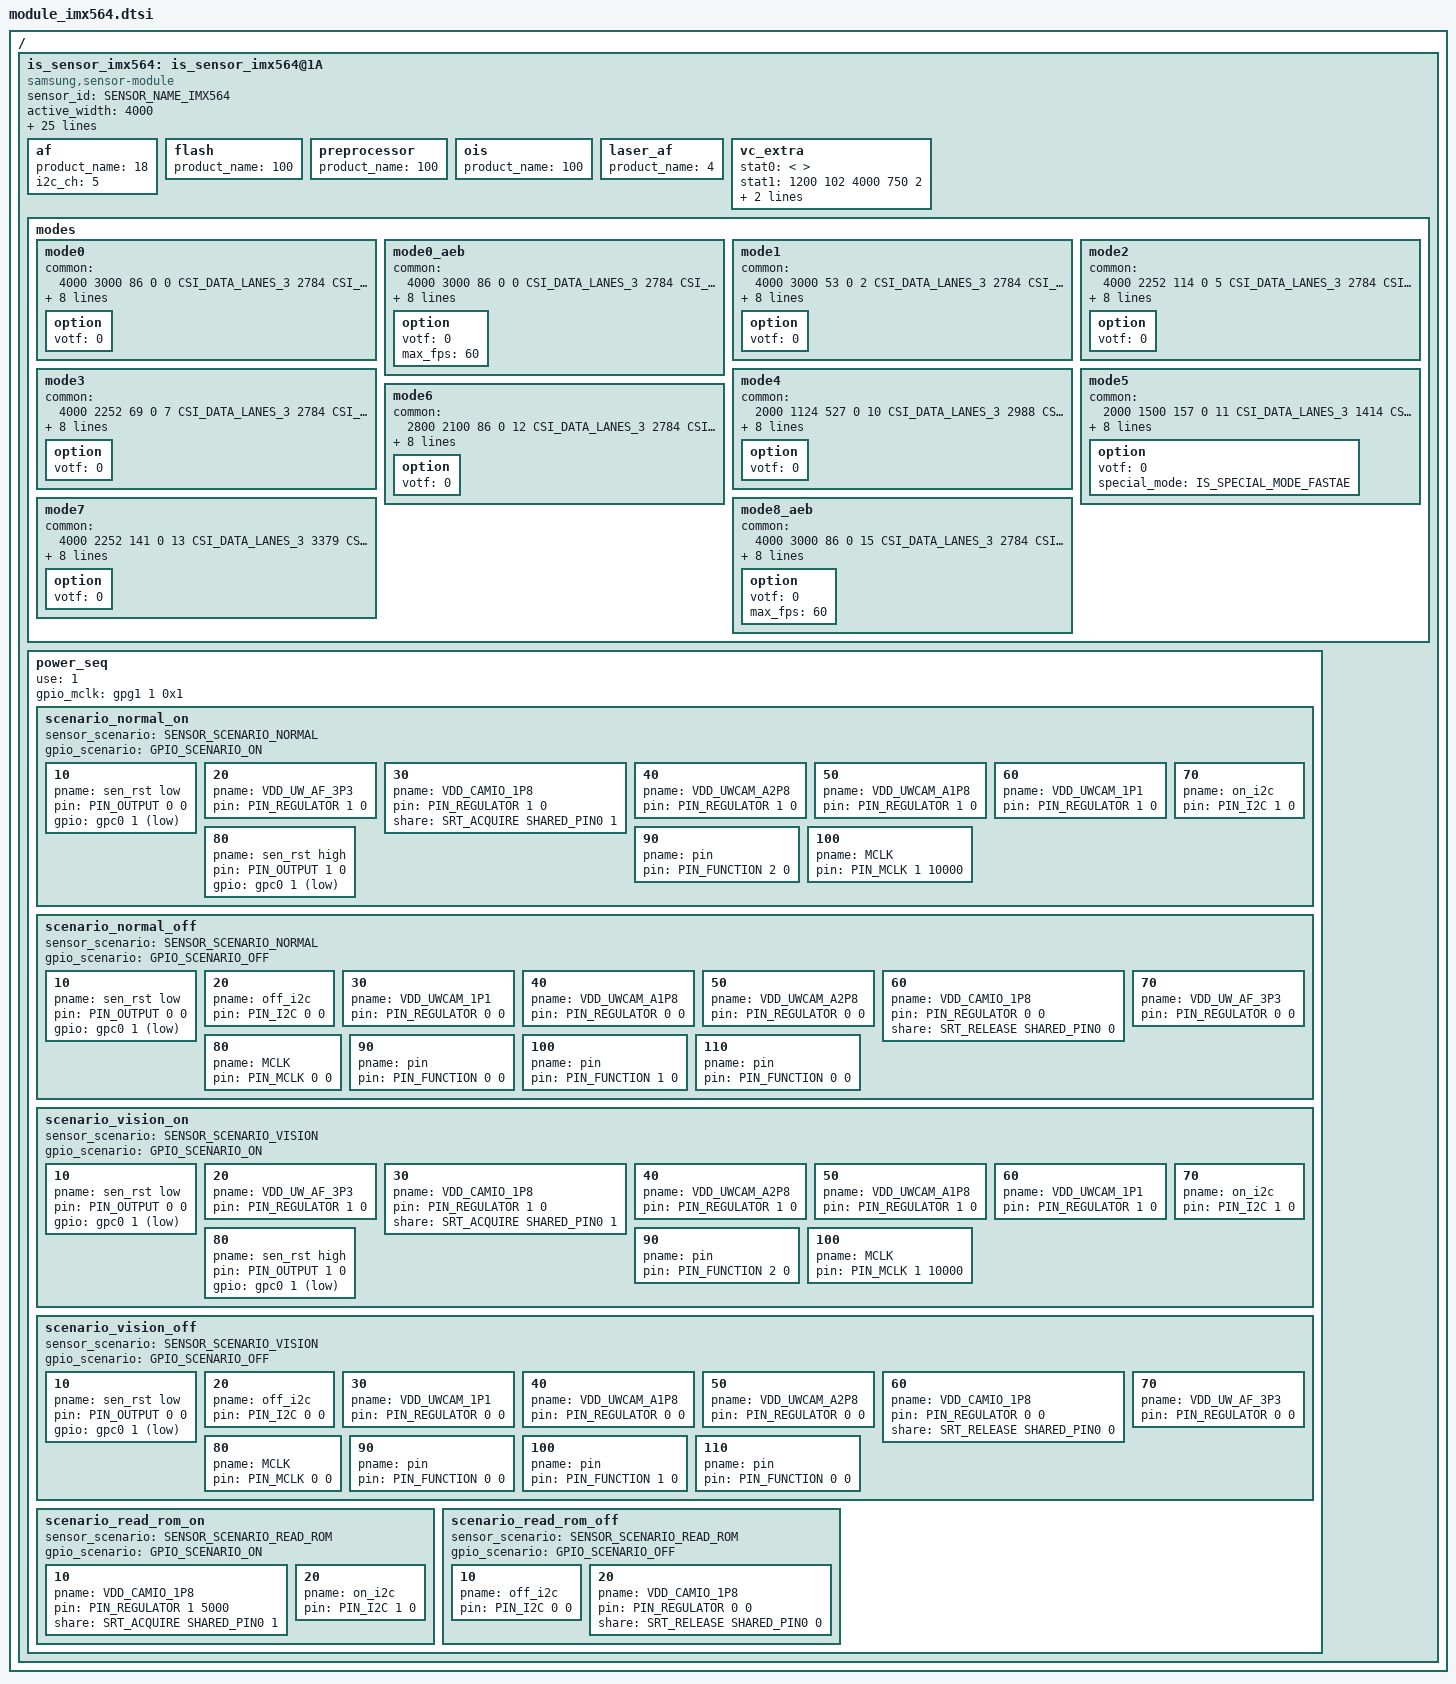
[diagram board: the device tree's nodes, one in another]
/*
 * SAMSUNG EXYNOSxxxx board camera device tree source
 *
 * Copyright (c) 2019 Samsung Electronics Co., Ltd.
 *		http://www.samsung.com
 *
 * This program is free software; you can redistribute it and/or modify
 * it under the terms of the GNU General Public License version 2 as
 * published by the Free Software Foundation.
 */

#include <dt-bindings/camera/exynos_is_dt.h>

/ {
	fragment@camera {
		target-path = "/";
		__overlay__ {
			is_sensor_imx564: is_sensor_imx564@1A {
				compatible = "samsung,sensor-module";

				/* common */
				sensor_id = <SENSOR_NAME_IMX564>;
				active_width = <4000>;
				active_height = <3000>;
				margin_left = <0>;
				margin_right = <0>;
				margin_top = <0>;
				margin_bottom = <0>;
				max_framerate = <480>;
				bitwidth = <10>;
				use_retention_mode = <SENSOR_RETENTION_UNSUPPORTED>;
				sensor_maker = "SONY";
				sensor_name = "IMX564";
				setfile_name = "setfile_imx564.bin";

				status = "okay";

				/* board */
				pinctrl-names = "pin0", "pin1", "pin2", "release";
				pinctrl-0 = <>;
				pinctrl-1 = <&sensor_mclk1_out>;
				pinctrl-2 = <&sensor_mclk1_fn>;
				pinctrl-3 = <>;

				position = <4>; /* Rear:0. Front:1, Tele:2, UW:4 */
				id = <4>; /* is_sensor id */
				mclk_ch = <1>;
				mclk_freq = <19200>;
				sensor_i2c_ch = <4>; /* SENSOR_CONTROL_I2C4 */

				/* vendor */
				rom_id = <2>;
				rom_cal_index = <0>;
				rom_dualcal_id = <0>;
				rom_dualcal_index = <0>;

				/* peri */
				af {
					product_name = <18>; /* ACTUATOR_NAME_AK737X */
					i2c_ch = <5>; /* SENSOR_CONTROL_I2C5 */
				};

				flash {
					product_name = <100>;  /* NOTHING product_name = <11>; FLASH_GPIO */
				};

				preprocessor {
					product_name = <100>; /* NOTHING */
				};

				ois {
					product_name = <100>; /* NOTHING */
				};

				laser_af {
					product_name = <4>; /* LASER_AF_NAME_VL53L8 */
				};

				vc_extra {
					/* ex) statX = <stat_type, sensor_mode, max_width, max_height, max_element> */
					stat0 = </* not available */>;									/* VC_BUF_DATA_TYPE_SENSOR_STAT1 */
					stat1 = </*VC_STAT_TYPE_PDP_4_1_PDAF_STAT0*/ 1200 /*VC_SENSOR_MODE_2PD_MODE3*/ 102 4000 750 2>;	/* VC_BUF_DATA_TYPE_GENERAL_STAT1 */
					stat2 = </* not available */>;									/* VC_BUF_DATA_TYPE_SENSOR_STAT2 */
					stat3 = </*VC_STAT_TYPE_PDP_4_1_PDAF_STAT1*/ 1201 /*VC_SENSOR_MODE_2PD_MODE3*/ 102 4000 750 2>;	/* VC_BUF_DATA_TYPE_GENERAL_STAT2 */
				};

				/* sensor modes */
				/*
					SENSOR_IMX564_4000X3000_86FPS_10BIT = 0,
					SENSOR_IMX564_4000X3000_53FPS_12BIT_LNFAST = 2,
					SENSOR_IMX564_4000X2252_114FPS_10BIT = 5,
					SENSOR_IMX564_4000X2252_69FPS_12BIT_LNFAST = 7,
					SENSOR_IMX564_2000X1124_527FPS = 10,
					SENSOR_IMX564_2000X1500_157FPS = 11,
					SENSOR_IMX564_2800X2100_86FPS = 12,
					SENSOR_IMX564_4000X2252_141FPS_10BIT = 13,
					SENSOR_IMX564_4000X3000_86FPS_12BIT = 15,
				*/
				modes {
						/* common = <width, height, fps, settle, mode, lane, speed, interleave, lrte, pd_mode> */
						/* vcX = <map, hwformat, width, height, hwformat, type, width, height> */
					mode0 {
						common = <4000 3000 86 0 0 CSI_DATA_LANES_3 2784 CSI_MODE_VC_ONLY LRTE_ENABLE PD_MOD3>;
						vc0 = </* in */ 0 HW_FORMAT_RAW10 DATA_IMG 4000 3000	/* out */ HW_FORMAT_RAW10 VC_NOTHING 4000 3000>;
						vc1 = </* in */ 2 HW_FORMAT_UNKNOWN DATA_NONE 0 0		/* out */ HW_FORMAT_UNKNOWN VC_NOTHING 0 0>;
						vc2 = </* in */ 1 HW_FORMAT_RAW10_POTF DATA_HPD 4000 750	/* out */ HW_FORMAT_RAW10_POTF_PACK VC_TAILPDAF 4000 750>;
						vc3 = </* in */ 3 HW_FORMAT_UNKNOWN DATA_NONE 0 0		/* out */ HW_FORMAT_UNKNOWN VC_NOTHING 0 0>;
						option { votf = <0>; };
					};
					mode0_aeb {
						common = <4000 3000 86 0 0 CSI_DATA_LANES_3 2784 CSI_MODE_VC_DT LRTE_ENABLE PD_MOD3 EX_AEB>;
						vc0 = </* in */ 0 HW_FORMAT_RAW10 DATA_IMG 4000 3000	/* out */ HW_FORMAT_RAW10 VC_NOTHING 4000 3000>;
						vc1 = </* in */ 2 HW_FORMAT_RAW10 DATA_IMG 4000 3000	/* out */ HW_FORMAT_RAW10 VC_NOTHING 4000 3000>;
						vc2 = </* in */ 1 HW_FORMAT_RAW10_POTF DATA_HPD 4000 750	/* out */ HW_FORMAT_RAW10_POTF_PACK VC_TAILPDAF 4000 750>;
						vc3 = </* in */ 3 HW_FORMAT_RAW10_POTF DATA_HPD 4000 750	/* out */ HW_FORMAT_UNKNOWN VC_NOTHING 0 0>;
						option { votf = <0>; max_fps = <60>; };
					};
					mode1 {
						common = <4000 3000 53 0 2 CSI_DATA_LANES_3 2784 CSI_MODE_VC_ONLY LRTE_ENABLE PD_MOD3>;
						vc0 = </* in */ 0 HW_FORMAT_RAW12 DATA_IMG 4000 3000	/* out */ HW_FORMAT_RAW12 VC_NOTHING 4000 3000>;
						vc1 = </* in */ 2 HW_FORMAT_UNKNOWN DATA_NONE 0 0		/* out */ HW_FORMAT_UNKNOWN VC_NOTHING 0 0>;
						vc2 = </* in */ 1 HW_FORMAT_RAW10_POTF DATA_HPD 4000 750	/* out */ HW_FORMAT_RAW10_POTF_PACK VC_TAILPDAF 4000 750>;
						vc3 = </* in */ 3 HW_FORMAT_UNKNOWN DATA_NONE 0 0		/* out */ HW_FORMAT_UNKNOWN VC_NOTHING 0 0>;
						option { votf = <0>; };
					};
					mode2 {
						common = <4000 2252 114 0 5 CSI_DATA_LANES_3 2784 CSI_MODE_VC_ONLY LRTE_ENABLE PD_MOD3>;
						vc0 = </* in */ 0 HW_FORMAT_RAW10 DATA_IMG 4000 2252	/* out */ HW_FORMAT_RAW10 VC_NOTHING 4000 2252>;
						vc1 = </* in */ 2 HW_FORMAT_UNKNOWN DATA_NONE 0 0		/* out */ HW_FORMAT_UNKNOWN VC_NOTHING 0 0>;
						vc2 = </* in */ 1 HW_FORMAT_RAW10_POTF DATA_HPD 4000 563	/* out */ HW_FORMAT_RAW10_POTF_PACK VC_TAILPDAF 4000 563>;
						vc3 = </* in */ 3 HW_FORMAT_UNKNOWN DATA_NONE 0 0		/* out */ HW_FORMAT_UNKNOWN VC_NOTHING 0 0>;
						option { votf = <0>; };
					};
					mode3 {
						common = <4000 2252 69 0 7 CSI_DATA_LANES_3 2784 CSI_MODE_VC_ONLY LRTE_ENABLE PD_MOD3>;
						vc0 = </* in */ 0 HW_FORMAT_RAW12 DATA_IMG 4000 2252	/* out */ HW_FORMAT_RAW12 VC_NOTHING 4000 2252>;
						vc1 = </* in */ 2 HW_FORMAT_UNKNOWN DATA_NONE 0 0		/* out */ HW_FORMAT_UNKNOWN VC_NOTHING 0 0>;
						vc2 = </* in */ 1 HW_FORMAT_RAW10_POTF DATA_HPD 4000 563	/* out */ HW_FORMAT_RAW10_POTF_PACK VC_TAILPDAF 4000 563>;
						vc3 = </* in */ 3 HW_FORMAT_UNKNOWN DATA_NONE 0 0		/* out */ HW_FORMAT_UNKNOWN VC_NOTHING 0 0>;
						option { votf = <0>; };
					};
					mode4 {
						common = <2000 1124 527 0 10 CSI_DATA_LANES_3 2988 CSI_MODE_VC_ONLY LRTE_ENABLE PD_MOD3>;
						vc0 = </* in */ 0 HW_FORMAT_RAW10 DATA_IMG 2000 1124	/* out */ HW_FORMAT_RAW10 VC_NOTHING 2000 1124>;
						vc1 = </* in */ 2 HW_FORMAT_UNKNOWN DATA_NONE 0 0		/* out */ HW_FORMAT_UNKNOWN VC_NOTHING 0 0>;
						vc2 = </* in */ 1 HW_FORMAT_RAW10_POTF DATA_HPD 2000 281	/* out */ HW_FORMAT_RAW10_POTF_PACK VC_TAILPDAF 2000 281>;
						vc3 = </* in */ 3 HW_FORMAT_UNKNOWN DATA_NONE 0 0		/* out */ HW_FORMAT_UNKNOWN VC_NOTHING 0 0>;
						option { votf = <0>; };
					};
					mode5 {
						common = <2000 1500 157 0 11 CSI_DATA_LANES_3 1414 CSI_MODE_VC_ONLY LRTE_ENABLE PD_MOD3>;
						vc0 = </* in */ 0 HW_FORMAT_RAW10 DATA_IMG 2000 1500	/* out */ HW_FORMAT_RAW10 VC_NOTHING 2000 1500>;
						vc1 = </* in */ 2 HW_FORMAT_UNKNOWN DATA_NONE 0 0		/* out */ HW_FORMAT_UNKNOWN VC_NOTHING 0 0>;
						vc2 = </* in */ 1 HW_FORMAT_RAW10_POTF DATA_HPD 2000 375	/* out */ HW_FORMAT_RAW10_POTF_PACK VC_TAILPDAF 2000 375>;
						vc3 = </* in */ 3 HW_FORMAT_UNKNOWN DATA_NONE 0 0		/* out */ HW_FORMAT_UNKNOWN VC_NOTHING 0 0>;
						option { votf = <0>; special_mode = <IS_SPECIAL_MODE_FASTAE>; };
					};
					mode6 {
						common = <2800 2100 86 0 12 CSI_DATA_LANES_3 2784 CSI_MODE_VC_ONLY LRTE_ENABLE PD_MOD3>;
						vc0 = </* in */ 0 HW_FORMAT_RAW10 DATA_IMG 2800 2100	/* out */ HW_FORMAT_RAW10 VC_NOTHING 2800 2100>;
						vc1 = </* in */ 2 HW_FORMAT_UNKNOWN DATA_NONE 0 0		/* out */ HW_FORMAT_UNKNOWN VC_NOTHING 0 0>;
						vc2 = </* in */ 1 HW_FORMAT_RAW10_POTF DATA_HPD 2800 525	/* out */ HW_FORMAT_RAW10_POTF_PACK VC_TAILPDAF 2800 525>;
						vc3 = </* in */ 3 HW_FORMAT_UNKNOWN DATA_NONE 0 0		/* out */ HW_FORMAT_UNKNOWN VC_NOTHING 0 0>;
						option { votf = <0>; };
					};
					mode7 {
						common = <4000 2252 141 0 13 CSI_DATA_LANES_3 3379 CSI_MODE_VC_ONLY LRTE_ENABLE PD_MOD3>;
						vc0 = </* in */ 0 HW_FORMAT_RAW10 DATA_IMG 4000 2252	/* out */ HW_FORMAT_RAW10 VC_NOTHING 4000 2252>;
						vc1 = </* in */ 2 HW_FORMAT_UNKNOWN DATA_NONE 0 0		/* out */ HW_FORMAT_UNKNOWN VC_NOTHING 0 0>;
						vc2 = </* in */ 1 HW_FORMAT_RAW10_POTF DATA_HPD 4000 563	/* out */ HW_FORMAT_RAW10_POTF_PACK VC_TAILPDAF 4000 563>;
						vc3 = </* in */ 3 HW_FORMAT_UNKNOWN DATA_NONE 0 0		/* out */ HW_FORMAT_UNKNOWN VC_NOTHING 0 0>;
						option { votf = <0>; };
					};
					mode8_aeb {
						common = <4000 3000 86 0 15 CSI_DATA_LANES_3 2784 CSI_MODE_VC_DT LRTE_ENABLE PD_MOD3 EX_AEB>;
						vc0 = </* in */ 0 HW_FORMAT_RAW12 DATA_IMG 4000 3000	/* out */ HW_FORMAT_RAW12 VC_NOTHING 4000 3000>;
						vc1 = </* in */ 2 HW_FORMAT_RAW12 DATA_IMG 4000 3000	/* out */ HW_FORMAT_RAW12 VC_NOTHING 4000 3000>;
						vc2 = </* in */ 1 HW_FORMAT_RAW10_POTF DATA_HPD 4000 750	/* out */ HW_FORMAT_RAW10_POTF_PACK VC_TAILPDAF 4000 750>;
						vc3 = </* in */ 3 HW_FORMAT_RAW10_POTF DATA_HPD 4000 750	/* out */ HW_FORMAT_UNKNOWN VC_NOTHING 0 0>;
						option { votf = <0>; max_fps = <60>; };
					};
				};

				power_seq {
					use = <1>;
					gpio_mclk = <&gpg1 1 0x1>;
					scenario_normal_on {
						sensor_scenario = <SENSOR_SCENARIO_NORMAL>;
						gpio_scenario = <GPIO_SCENARIO_ON>;

						/* A start node number should be over the 10 for reserved number 0~9. */
						/* pname = "name"; pin = <act value delay voltage>; gpio = <gpx# # 0x1>; */
						//5 { pname = "vdd_hldo"; pin = <PIN_REGULATOR_VOLTAGE 0 0 3500000>; share = <SRT_ACQUIRE SHARED_PIN3 1>; };
						10 { pname = "sen_rst low"; pin = <PIN_OUTPUT 0 0>; gpio = <&gpc0 1 0x1>; };
						20 { pname = "VDD_UW_AF_3P3"; pin = <PIN_REGULATOR 1 0>; };
						30 { pname = "VDD_CAMIO_1P8"; pin = <PIN_REGULATOR 1 0>; share = <SRT_ACQUIRE SHARED_PIN0 1>; };
						40 { pname = "VDD_UWCAM_A2P8"; pin = <PIN_REGULATOR 1 0>; };
						50 { pname = "VDD_UWCAM_A1P8"; pin = <PIN_REGULATOR 1 0>; };
						60 { pname = "VDD_UWCAM_1P1"; pin = <PIN_REGULATOR 1 0>; };
						70 { pname = "on_i2c"; pin = <PIN_I2C 1 0>; };
						80 { pname = "sen_rst high"; pin = <PIN_OUTPUT 1 0>; gpio = <&gpc0 1 0x1>; };
						90 { pname = "pin"; pin = <PIN_FUNCTION 2 0>; };
						100 { pname = "MCLK"; pin = <PIN_MCLK 1 10000>; };
					};

					scenario_normal_off {
						sensor_scenario = <SENSOR_SCENARIO_NORMAL>;
						gpio_scenario = <GPIO_SCENARIO_OFF>;

						/* A start node number should be over the 10 for reserved number 0~9. */
						/* pname = "name"; pin = <act value delay voltage>; gpio = <gpx# # 0x1>; */
						10 { pname = "sen_rst low"; pin = <PIN_OUTPUT 0 0>; gpio = <&gpc0 1 0x1>; };
						20 { pname = "off_i2c"; pin = <PIN_I2C 0 0>; };
						30 { pname = "VDD_UWCAM_1P1"; pin = <PIN_REGULATOR 0 0>; };
						40 { pname = "VDD_UWCAM_A1P8"; pin = <PIN_REGULATOR 0 0>; };
						50 { pname = "VDD_UWCAM_A2P8"; pin = <PIN_REGULATOR 0 0>; };
						60 { pname = "VDD_CAMIO_1P8"; pin = <PIN_REGULATOR 0 0>; share = <SRT_RELEASE SHARED_PIN0 0>; };
						70 { pname = "VDD_UW_AF_3P3"; pin = <PIN_REGULATOR 0 0>; };
						80 { pname = "MCLK"; pin = <PIN_MCLK 0 0>; };
						90 { pname = "pin"; pin = <PIN_FUNCTION 0 0>; };
						100 { pname = "pin"; pin = <PIN_FUNCTION 1 0>; };
						110 { pname = "pin"; pin = <PIN_FUNCTION 0 0>; };
						//120 { pname = "vdd_hldo"; pin = <PIN_REGULATOR_VOLTAGE 0 0 3400000>; share = <SRT_RELEASE SHARED_PIN3 0>; };
					};

					scenario_vision_on {
						sensor_scenario = <SENSOR_SCENARIO_VISION>;
						gpio_scenario = <GPIO_SCENARIO_ON>;

						/* A start node number should be over the 10 for reserved number 0~9. */
						/* pname = "name"; pin = <act value delay voltage>; gpio = <gpx# # 0x1>; */
						//5 { pname = "vdd_hldo"; pin = <PIN_REGULATOR_VOLTAGE 0 0 3500000>; share = <SRT_ACQUIRE SHARED_PIN3 1>; };
						10 { pname = "sen_rst low"; pin = <PIN_OUTPUT 0 0>; gpio = <&gpc0 1 0x1>; };
						20 { pname = "VDD_UW_AF_3P3"; pin = <PIN_REGULATOR 1 0>; };
						30 { pname = "VDD_CAMIO_1P8"; pin = <PIN_REGULATOR 1 0>; share = <SRT_ACQUIRE SHARED_PIN0 1>; };
						40 { pname = "VDD_UWCAM_A2P8"; pin = <PIN_REGULATOR 1 0>; };
						50 { pname = "VDD_UWCAM_A1P8"; pin = <PIN_REGULATOR 1 0>; };
						60 { pname = "VDD_UWCAM_1P1"; pin = <PIN_REGULATOR 1 0>; };
						70 { pname = "on_i2c"; pin = <PIN_I2C 1 0>; };
						80 { pname = "sen_rst high"; pin = <PIN_OUTPUT 1 0>; gpio = <&gpc0 1 0x1>; };
						90 { pname = "pin"; pin = <PIN_FUNCTION 2 0>; };
						100 { pname = "MCLK"; pin = <PIN_MCLK 1 10000>; };
					};

					scenario_vision_off {
						sensor_scenario = <SENSOR_SCENARIO_VISION>;
						gpio_scenario = <GPIO_SCENARIO_OFF>;

						/* A start node number should be over the 10 for reserved number 0~9. */
						/* pname = "name"; pin = <act value delay voltage>; gpio = <gpx# # 0x1>; */
						10 { pname = "sen_rst low"; pin = <PIN_OUTPUT 0 0>; gpio = <&gpc0 1 0x1>; };
						20 { pname = "off_i2c"; pin = <PIN_I2C 0 0>; };
						30 { pname = "VDD_UWCAM_1P1"; pin = <PIN_REGULATOR 0 0>; };
						40 { pname = "VDD_UWCAM_A1P8"; pin = <PIN_REGULATOR 0 0>; };
						50 { pname = "VDD_UWCAM_A2P8"; pin = <PIN_REGULATOR 0 0>; };
						60 { pname = "VDD_CAMIO_1P8"; pin = <PIN_REGULATOR 0 0>; share = <SRT_RELEASE SHARED_PIN0 0>; };
						70 { pname = "VDD_UW_AF_3P3"; pin = <PIN_REGULATOR 0 0>; };
						80 { pname = "MCLK"; pin = <PIN_MCLK 0 0>; };
						90 { pname = "pin"; pin = <PIN_FUNCTION 0 0>; };
						100 { pname = "pin"; pin = <PIN_FUNCTION 1 0>; };
						110 { pname = "pin"; pin = <PIN_FUNCTION 0 0>; };
						//120 { pname = "vdd_hldo"; pin = <PIN_REGULATOR_VOLTAGE 0 0 3400000>; share = <SRT_RELEASE SHARED_PIN3 0>; };
					};

					scenario_read_rom_on {
						sensor_scenario = <SENSOR_SCENARIO_READ_ROM>;
						gpio_scenario = <GPIO_SCENARIO_ON>;

						/* A start node number should be over the 10 for reserved number 0~9. */
						/* pname = "name"; pin = <act value delay voltage>; gpio = <gpx# # 0x1>; */
						10 { pname = "VDD_CAMIO_1P8"; pin = <PIN_REGULATOR 1 5000>; share = <SRT_ACQUIRE SHARED_PIN0 1>; };
						20 { pname = "on_i2c"; pin = <PIN_I2C 1 0>; };
					};

					scenario_read_rom_off {
						sensor_scenario = <SENSOR_SCENARIO_READ_ROM>;
						gpio_scenario = <GPIO_SCENARIO_OFF>;

						/* A start node number should be over the 10 for reserved number 0~9. */
						/* pname = "name"; pin = <act value delay voltage>; gpio = <gpx# # 0x1>; */
						10 { pname = "off_i2c"; pin = <PIN_I2C 0 0>; };
						20 { pname = "VDD_CAMIO_1P8"; pin = <PIN_REGULATOR 0 0>; share = <SRT_RELEASE SHARED_PIN0 0>; };
					};
				};
			};
		}; /* end of __overlay__ */
	}; /* end of fragment */
}; /* end of root */
